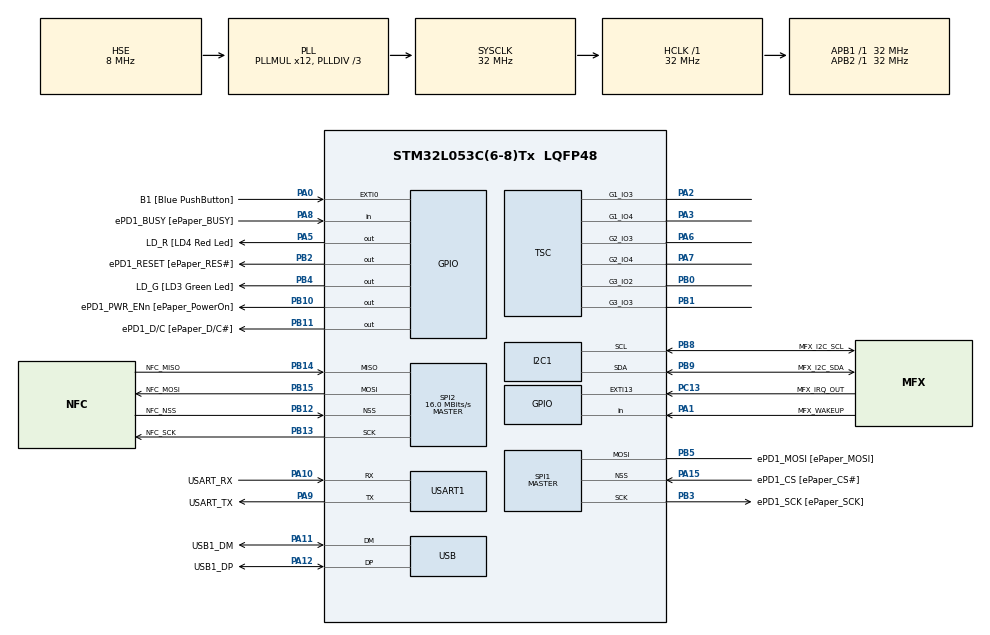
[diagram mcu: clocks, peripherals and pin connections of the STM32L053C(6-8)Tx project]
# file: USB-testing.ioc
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Mcu.Family=STM32L0
Mcu.Name=STM32L053C(6-8)Tx
Mcu.Package=LQFP48
NVIC.USB_IRQn=true\:0\:0\:false\:false\:true\:false\:true\:true
PA0.GPIO_Label=B1 [Blue PushButton]
PA0.GPIO_ModeDefaultEXTI=GPIO_MODE_EVT_RISING
PA0.GPIO_PuPd=GPIO_NOPULL
PA0.Signal=GPXTI0
PA1.GPIO_Label=MFX_WAKEUP
PA1.Signal=GPIO_Input
PA10.GPIO_Label=USART_RX
PA10.Mode=Asynchronous
PA10.Signal=USART1_RX
PA11.GPIO_Label=USB1_DM
PA11.Mode=Device
PA11.Signal=USB_DM
PA12.GPIO_Label=USB1_DP
PA12.Mode=Device
PA12.Signal=USB_DP
PA13.GPIO_Label=SWDIO
PA13.Mode=Serial_Wire
PA13.Signal=SYS_SWDIO
PA14.GPIO_Label=SWCLK
PA14.Mode=Serial_Wire
PA14.Signal=SYS_SWCLK
PA15.GPIO_Label=ePD1_CS [ePaper_CS\#]
PA15.GPIO_Mode=GPIO_MODE_AF_PP
PA15.GPIO_PuPd=GPIO_NOPULL
PA15.GPIO_Speed=GPIO_SPEED_FREQ_LOW
PA15.Mode=NSS_Signal_Hard_Input
PA15.Signal=SPI1_NSS
PA2.Mode=G1_IO3-Channel
PA2.Signal=TSC_G1_IO3
PA3.Mode=G1_IO4-Sampling
PA3.Signal=TSC_G1_IO4
PA5.GPIO_Label=LD_R [LD4 Red Led]
PA5.GPIO_ModeDefaultOutputPP=GPIO_MODE_OUTPUT_PP
PA5.GPIO_PuPd=GPIO_NOPULL
PA5.GPIO_Speed=GPIO_SPEED_FREQ_LOW
PA5.Signal=GPIO_Output
PA6.Mode=G2_IO3-Channel
PA6.Signal=TSC_G2_IO3
PA7.Mode=G2_IO4-Sampling
PA7.Signal=TSC_G2_IO4
PA8.GPIO_Label=ePD1_BUSY [ePaper_BUSY]
PA8.GPIO_Mode=GPIO_MODE_INPUT
PA8.GPIO_PuPd=GPIO_NOPULL
PA8.Signal=GPIO_Input
PA9.GPIO_Label=USART_TX
PA9.Mode=Asynchronous
PA9.Signal=USART1_TX
PB0.Mode=G3_IO2-Channel
PB0.Signal=TSC_G3_IO2
PB1.Mode=G3_IO3-Sampling
PB1.Signal=TSC_G3_IO3
PB10.GPIO_Label=ePD1_PWR_ENn [ePaper_PowerOn]
PB10.GPIO_ModeDefaultOutputPP=GPIO_MODE_OUTPUT_PP
PB10.GPIO_PuPd=GPIO_NOPULL
PB10.GPIO_Speed=GPIO_SPEED_FREQ_LOW
PB10.Signal=GPIO_Output
PB11.GPIO_Label=ePD1_D/C [ePaper_D/C\#]
PB11.GPIO_ModeDefaultOutputPP=GPIO_MODE_OUTPUT_PP
PB11.GPIO_PuPd=GPIO_NOPULL
PB11.GPIO_Speed=GPIO_SPEED_FREQ_LOW
PB11.Signal=GPIO_Output
PB12.GPIO_Label=NFC_NSS
PB12.Mode=NSS_Signal_Hard_Input
PB12.Signal=SPI2_NSS
PB13.GPIO_Label=NFC_SCK
PB13.Mode=Full_Duplex_Master
PB13.Signal=SPI2_SCK
PB14.GPIO_Label=NFC_MISO
PB14.Mode=Full_Duplex_Master
PB14.Signal=SPI2_MISO
PB15.GPIO_Label=NFC_MOSI
PB15.Mode=Full_Duplex_Master
PB15.Signal=SPI2_MOSI
PB2.GPIO_Label=ePD1_RESET [ePaper_RES\#]
PB2.GPIO_ModeDefaultOutputPP=GPIO_MODE_OUTPUT_PP
PB2.GPIO_PuPd=GPIO_NOPULL
PB2.GPIO_Speed=GPIO_SPEED_FREQ_LOW
PB2.Signal=GPIO_Output
PB3.GPIO_Label=ePD1_SCK [ePaper_SCK]
PB3.GPIO_Mode=GPIO_MODE_AF_PP
PB3.GPIO_PuPd=GPIO_NOPULL
PB3.GPIO_Speed=GPIO_SPEED_FREQ_LOW
PB3.Mode=Simplex_Bidirectional_Master
PB3.Signal=SPI1_SCK
PB4.GPIO_Label=LD_G [LD3 Green Led]
PB4.GPIO_ModeDefaultOutputPP=GPIO_MODE_OUTPUT_PP
PB4.GPIO_PuPd=GPIO_NOPULL
PB4.GPIO_Speed=GPIO_SPEED_FREQ_LOW
PB4.Signal=GPIO_Output
PB5.GPIO_Label=ePD1_MOSI [ePaper_MOSI]
PB5.GPIO_Mode=GPIO_MODE_AF_PP
PB5.GPIO_PuPd=GPIO_NOPULL
PB5.GPIO_Speed=GPIO_SPEED_FREQ_LOW
PB5.Mode=Simplex_Bidirectional_Master
PB5.Signal=SPI1_MOSI
PB8.GPIO_Label=MFX_I2C_SCL
PB8.GPIO_Pu=GPIO_PULLUP
PB8.Mode=I2C
PB8.Signal=I2C1_SCL
PB9.GPIO_Label=MFX_I2C_SDA
PB9.GPIO_Pu=GPIO_PULLUP
PB9.Mode=I2C
PB9.Signal=I2C1_SDA
PC13.GPIO_Label=MFX_IRQ_OUT
PC13.Signal=GPXTI13
PC14-OSC32_IN.GPIO_Label=PC14-OSC32_IN
PC14-OSC32_IN.Signal=RCC_OSC32_IN
PC15-OSC32_OUT.GPIO_Label=PC15-OSC32_OUT
PC15-OSC32_OUT.Signal=RCC_OSC32_OUT
PH0-OSC_IN.GPIO_Label=MCO
PH0-OSC_IN.Mode=HSE-External-Clock-Source
PH0-OSC_IN.Signal=RCC_OSC_IN
ProjectManager.HeapSize=0x200
ProjectManager.StackSize=0x400
ProjectManager.TargetToolchain=STM32CubeIDE
RCC.AHBFreq_Value=32000000
RCC.APB1Freq_Value=32000000
RCC.APB1TimFreq_Value=32000000
RCC.APB2Freq_Value=32000000
RCC.APB2TimFreq_Value=32000000
RCC.HCLKFreq_Value=32000000
RCC.HSE_VALUE=8000000
RCC.HSI16_VALUE=16000000
RCC.HSI48MClockSelection=RCC_USBCLKSOURCE_HSI48
RCC.HSI48_VALUE=48000000
RCC.HSI_VALUE=16000000
RCC.LSE_VALUE=32768
RCC.MSI_VALUE=2097000
RCC.PLLDIV=RCC_PLLDIV_3
RCC.PLLMUL=RCC_PLLMUL_12
RCC.PLLSourceVirtual=RCC_PLLSOURCE_HSE
RCC.RTCClockSelectionVirtual=RCC_RTCCLKSOURCE_LSE
RCC.SYSCLKFreq_VALUE=32000000
RCC.SYSCLKSource=RCC_SYSCLKSOURCE_PLLCLK
RCC.VCOOutputFreq_Value=96000000
SPI1.CalculateBaudRate-Simplex_Bidirectional_Master=16.0 MBits/s
SPI1.Direction=SPI_DIRECTION_1LINE
SPI1.Direction-Simplex_Bidirectional_Master=SPI_DIRECTION_1LINE
SPI1.Mode=SPI_MODE_MASTER
SPI1.Mode-Simplex_Bidirectional_Master=SPI_MODE_MASTER
SPI1.NSS-Simplex_Bidirectional_Master=SPI_NSS_HARD_OUTPUT
SPI1.TIMode-Simplex_Bidirectional_Master=SPI_TIMODE_DISABLE
SPI1.VirtualNSS=VM_NSSHARD
SPI1.VirtualType=VM_MASTER
SPI2.CalculateBaudRate=16.0 MBits/s
SPI2.Direction=SPI_DIRECTION_2LINES
SPI2.Mode=SPI_MODE_MASTER
SPI2.VirtualNSS=VM_NSSHARD
SPI2.VirtualType=VM_MASTER
USART1.VirtualMode-Asynchronous=VM_ASYNC
USB_DEVICE.CLASS_NAME_FS=CUSTOM_HID
USB_DEVICE.VirtualMode=CustomHid
USB_DEVICE.VirtualModeFS=Custom_Hid_FS
VP_USB_DEVICE_VS_USB_DEVICE_CUSTOM_HID_FS.Mode=CUSTOM_HID_FS
board=STM32L0538-DISCO

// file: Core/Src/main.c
/* USER CODE BEGIN Header */
/**
  ******************************************************************************
  * @file           : main.c
  * @brief          : Main program body
  ******************************************************************************
  * @attention
  *
  * Copyright (c) 2025 STMicroelectronics.
  * All rights reserved.
  *
  * This software is licensed under terms that can be found in the LICENSE file
  * in the root directory of this software component.
  * If no LICENSE file comes with this software, it is provided AS-IS.
  *
  ******************************************************************************
  */
/* USER CODE END Header */
#include "main.h"
#include "usb_device.h"
#include "usbd_custom_hid_if.h"

I2C_HandleTypeDef hi2c1;

SPI_HandleTypeDef hspi1;
SPI_HandleTypeDef hspi2;

TSC_HandleTypeDef htsc;

UART_HandleTypeDef huart1;

void SystemClock_Config(void);
static void MX_GPIO_Init(void);
static void MX_I2C1_Init(void);
static void MX_SPI1_Init(void);
static void MX_SPI2_Init(void);
static void MX_TSC_Init(void);
static void MX_USART1_UART_Init(void);

int main(void)
{

  /* MCU Configuration--------------------------------------------------------*/

  /* Reset of all peripherals, Initializes the Flash interface and the Systick. */
  HAL_Init();

  /* Configure the system clock */
  SystemClock_Config();

  /* Initialize all configured peripherals */
  MX_GPIO_Init();
  MX_I2C1_Init();
  MX_SPI1_Init();
  MX_SPI2_Init();
  MX_TSC_Init();
  MX_USART1_UART_Init();
  MX_USB_DEVICE_Init();

  /* Infinite loop */
  while (1)
  {

    /* USER CODE BEGIN 3 */
	  for(int i =0 ; i < 50000;i++){}
	  HAL_GPIO_TogglePin(LD_G_GPIO_Port, LD_G_Pin);
  }
  /* USER CODE END 3 */
}

void SystemClock_Config(void)
{
  RCC_OscInitTypeDef RCC_OscInitStruct = {0};
  RCC_ClkInitTypeDef RCC_ClkInitStruct = {0};
  RCC_PeriphCLKInitTypeDef PeriphClkInit = {0};

  /** Configure the main internal regulator output voltage
  */
  __HAL_PWR_VOLTAGESCALING_CONFIG(PWR_REGULATOR_VOLTAGE_SCALE1);

  /** Initializes the RCC Oscillators according to the specified parameters
  * in the RCC_OscInitTypeDef structure.
  */
  RCC_OscInitStruct.OscillatorType = RCC_OSCILLATORTYPE_HSE|RCC_OSCILLATORTYPE_HSI48;
  RCC_OscInitStruct.HSEState = RCC_HSE_BYPASS;
  RCC_OscInitStruct.HSI48State = RCC_HSI48_ON;
  RCC_OscInitStruct.PLL.PLLState = RCC_PLL_ON;
  RCC_OscInitStruct.PLL.PLLSource = RCC_PLLSOURCE_HSE;
  RCC_OscInitStruct.PLL.PLLMUL = RCC_PLLMUL_12;
  RCC_OscInitStruct.PLL.PLLDIV = RCC_PLLDIV_3;
  if (HAL_RCC_OscConfig(&RCC_OscInitStruct) != HAL_OK)
  {
    Error_Handler();
  }

  /** Initializes the CPU, AHB and APB buses clocks
  */
  RCC_ClkInitStruct.ClockType = RCC_CLOCKTYPE_HCLK|RCC_CLOCKTYPE_SYSCLK
                              |RCC_CLOCKTYPE_PCLK1|RCC_CLOCKTYPE_PCLK2;
  RCC_ClkInitStruct.SYSCLKSource = RCC_SYSCLKSOURCE_PLLCLK;
  RCC_ClkInitStruct.AHBCLKDivider = RCC_SYSCLK_DIV1;
  RCC_ClkInitStruct.APB1CLKDivider = RCC_HCLK_DIV1;
  RCC_ClkInitStruct.APB2CLKDivider = RCC_HCLK_DIV1;

  if (HAL_RCC_ClockConfig(&RCC_ClkInitStruct, FLASH_LATENCY_1) != HAL_OK)
  {
    Error_Handler();
  }
  PeriphClkInit.PeriphClockSelection = RCC_PERIPHCLK_USART1|RCC_PERIPHCLK_I2C1
                              |RCC_PERIPHCLK_USB;
  PeriphClkInit.Usart1ClockSelection = RCC_USART1CLKSOURCE_PCLK2;
  PeriphClkInit.I2c1ClockSelection = RCC_I2C1CLKSOURCE_PCLK1;
  PeriphClkInit.UsbClockSelection = RCC_USBCLKSOURCE_HSI48;
  if (HAL_RCCEx_PeriphCLKConfig(&PeriphClkInit) != HAL_OK)
  {
    Error_Handler();
  }
}

static void MX_I2C1_Init(void)
{

  hi2c1.Instance = I2C1;
  hi2c1.Init.Timing = 0x00000708;
  hi2c1.Init.OwnAddress1 = 0;
  hi2c1.Init.AddressingMode = I2C_ADDRESSINGMODE_7BIT;
  hi2c1.Init.DualAddressMode = I2C_DUALADDRESS_DISABLE;
  hi2c1.Init.OwnAddress2 = 0;
  hi2c1.Init.OwnAddress2Masks = I2C_OA2_NOMASK;
  hi2c1.Init.GeneralCallMode = I2C_GENERALCALL_DISABLE;
  hi2c1.Init.NoStretchMode = I2C_NOSTRETCH_DISABLE;
  if (HAL_I2C_Init(&hi2c1) != HAL_OK)
  {
    Error_Handler();
  }

  /** Configure Analogue filter
  */
  if (HAL_I2CEx_ConfigAnalogFilter(&hi2c1, I2C_ANALOGFILTER_ENABLE) != HAL_OK)
  {
    Error_Handler();
  }

  /** Configure Digital filter
  */
  if (HAL_I2CEx_ConfigDigitalFilter(&hi2c1, 0) != HAL_OK)
  {
    Error_Handler();
  }

}

static void MX_SPI1_Init(void)
{

  /* SPI1 parameter configuration*/
  hspi1.Instance = SPI1;
  hspi1.Init.Mode = SPI_MODE_MASTER;
  hspi1.Init.Direction = SPI_DIRECTION_1LINE;
  hspi1.Init.DataSize = SPI_DATASIZE_8BIT;
  hspi1.Init.CLKPolarity = SPI_POLARITY_LOW;
  hspi1.Init.CLKPhase = SPI_PHASE_1EDGE;
  hspi1.Init.NSS = SPI_NSS_HARD_INPUT;
  hspi1.Init.BaudRatePrescaler = SPI_BAUDRATEPRESCALER_2;
  hspi1.Init.FirstBit = SPI_FIRSTBIT_MSB;
  hspi1.Init.TIMode = SPI_TIMODE_DISABLE;
  hspi1.Init.CRCCalculation = SPI_CRCCALCULATION_DISABLE;
  hspi1.Init.CRCPolynomial = 7;
  if (HAL_SPI_Init(&hspi1) != HAL_OK)
  {
    Error_Handler();
  }

}

static void MX_SPI2_Init(void)
{

  /* SPI2 parameter configuration*/
  hspi2.Instance = SPI2;
  hspi2.Init.Mode = SPI_MODE_MASTER;
  hspi2.Init.Direction = SPI_DIRECTION_2LINES;
  hspi2.Init.DataSize = SPI_DATASIZE_8BIT;
  hspi2.Init.CLKPolarity = SPI_POLARITY_LOW;
  hspi2.Init.CLKPhase = SPI_PHASE_1EDGE;
  hspi2.Init.NSS = SPI_NSS_HARD_INPUT;
  hspi2.Init.BaudRatePrescaler = SPI_BAUDRATEPRESCALER_2;
  hspi2.Init.FirstBit = SPI_FIRSTBIT_MSB;
  hspi2.Init.TIMode = SPI_TIMODE_DISABLE;
  hspi2.Init.CRCCalculation = SPI_CRCCALCULATION_DISABLE;
  hspi2.Init.CRCPolynomial = 7;
  if (HAL_SPI_Init(&hspi2) != HAL_OK)
  {
    Error_Handler();
  }

}

static void MX_TSC_Init(void)
{

  /** Configure the TSC peripheral
  */
  htsc.Instance = TSC;
  htsc.Init.CTPulseHighLength = TSC_CTPH_2CYCLES;
  htsc.Init.CTPulseLowLength = TSC_CTPL_2CYCLES;
  htsc.Init.SpreadSpectrum = DISABLE;
  htsc.Init.SpreadSpectrumDeviation = 1;
  htsc.Init.SpreadSpectrumPrescaler = TSC_SS_PRESC_DIV1;
  htsc.Init.PulseGeneratorPrescaler = TSC_PG_PRESC_DIV4;
  htsc.Init.MaxCountValue = TSC_MCV_8191;
  htsc.Init.IODefaultMode = TSC_IODEF_OUT_PP_LOW;
  htsc.Init.SynchroPinPolarity = TSC_SYNC_POLARITY_FALLING;
  htsc.Init.AcquisitionMode = TSC_ACQ_MODE_NORMAL;
  htsc.Init.MaxCountInterrupt = DISABLE;
  htsc.Init.ChannelIOs = TSC_GROUP1_IO3|TSC_GROUP2_IO3|TSC_GROUP3_IO2;
  htsc.Init.ShieldIOs = 0;
  htsc.Init.SamplingIOs = TSC_GROUP1_IO4|TSC_GROUP2_IO4|TSC_GROUP3_IO3;
  if (HAL_TSC_Init(&htsc) != HAL_OK)
  {
    Error_Handler();
  }

}

static void MX_USART1_UART_Init(void)
{

  huart1.Instance = USART1;
  huart1.Init.BaudRate = 115200;
  huart1.Init.WordLength = UART_WORDLENGTH_8B;
  huart1.Init.StopBits = UART_STOPBITS_1;
  huart1.Init.Parity = UART_PARITY_NONE;
  huart1.Init.Mode = UART_MODE_TX_RX;
  huart1.Init.HwFlowCtl = UART_HWCONTROL_NONE;
  huart1.Init.OverSampling = UART_OVERSAMPLING_16;
  huart1.Init.OneBitSampling = UART_ONE_BIT_SAMPLE_DISABLE;
  huart1.AdvancedInit.AdvFeatureInit = UART_ADVFEATURE_NO_INIT;
  if (HAL_UART_Init(&huart1) != HAL_OK)
  {
    Error_Handler();
  }

}

static void MX_GPIO_Init(void)
{
  GPIO_InitTypeDef GPIO_InitStruct = {0};

  /* GPIO Ports Clock Enable */
  __HAL_RCC_GPIOC_CLK_ENABLE();
  __HAL_RCC_GPIOH_CLK_ENABLE();
  __HAL_RCC_GPIOA_CLK_ENABLE();
  __HAL_RCC_GPIOB_CLK_ENABLE();

  /*Configure GPIO pin Output Level */
  HAL_GPIO_WritePin(LD_R_GPIO_Port, LD_R_Pin, GPIO_PIN_RESET);

  /*Configure GPIO pin Output Level */
  HAL_GPIO_WritePin(GPIOB, ePD1_RESET_Pin|ePD1_PWR_ENn_Pin|ePD1_D_C_Pin|LD_G_Pin, GPIO_PIN_RESET);

  /*Configure GPIO pin : MFX_IRQ_OUT_Pin */
  GPIO_InitStruct.Pin = MFX_IRQ_OUT_Pin;
  GPIO_InitStruct.Mode = GPIO_MODE_IT_RISING;
  GPIO_InitStruct.Pull = GPIO_NOPULL;
  HAL_GPIO_Init(MFX_IRQ_OUT_GPIO_Port, &GPIO_InitStruct);

  /*Configure GPIO pin : B1_Pin */
  GPIO_InitStruct.Pin = B1_Pin;
  GPIO_InitStruct.Mode = GPIO_MODE_EVT_RISING;
  GPIO_InitStruct.Pull = GPIO_NOPULL;
  HAL_GPIO_Init(B1_GPIO_Port, &GPIO_InitStruct);

  /*Configure GPIO pins : MFX_WAKEUP_Pin ePD1_BUSY_Pin */
  GPIO_InitStruct.Pin = MFX_WAKEUP_Pin|ePD1_BUSY_Pin;
  GPIO_InitStruct.Mode = GPIO_MODE_INPUT;
  GPIO_InitStruct.Pull = GPIO_NOPULL;
  HAL_GPIO_Init(GPIOA, &GPIO_InitStruct);

  /*Configure GPIO pin : LD_R_Pin */
  GPIO_InitStruct.Pin = LD_R_Pin;
  GPIO_InitStruct.Mode = GPIO_MODE_OUTPUT_PP;
  GPIO_InitStruct.Pull = GPIO_NOPULL;
  GPIO_InitStruct.Speed = GPIO_SPEED_FREQ_LOW;
  HAL_GPIO_Init(LD_R_GPIO_Port, &GPIO_InitStruct);

  /*Configure GPIO pins : ePD1_RESET_Pin ePD1_PWR_ENn_Pin ePD1_D_C_Pin LD_G_Pin */
  GPIO_InitStruct.Pin = ePD1_RESET_Pin|ePD1_PWR_ENn_Pin|ePD1_D_C_Pin|LD_G_Pin;
  GPIO_InitStruct.Mode = GPIO_MODE_OUTPUT_PP;
  GPIO_InitStruct.Pull = GPIO_NOPULL;
  GPIO_InitStruct.Speed = GPIO_SPEED_FREQ_LOW;
  HAL_GPIO_Init(GPIOB, &GPIO_InitStruct);

}

void Error_Handler(void)
{
  /* USER CODE BEGIN Error_Handler_Debug */
  /* User can add his own implementation to report the HAL error return state */
  __disable_irq();
  while (1)
  {
	  HAL_GPIO_TogglePin(LD_R_GPIO_Port, LD_R_Pin);
	  HAL_Delay(500);
  }
  /* USER CODE END Error_Handler_Debug */
}
